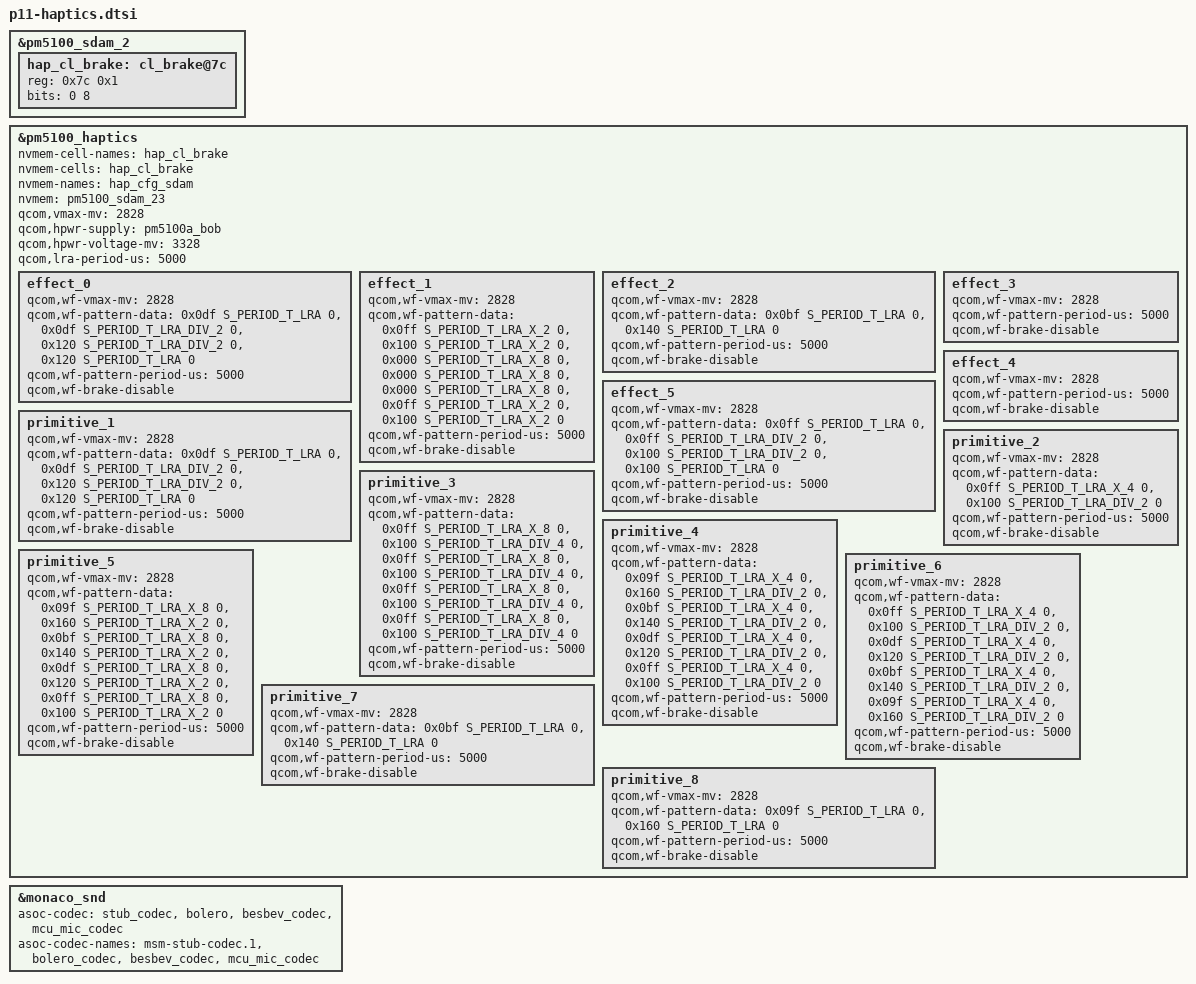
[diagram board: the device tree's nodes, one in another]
// SPDX-License-Identifier: GPL-2.0

&pm5100_sdam_2 {
	#address-cells = <1>;
	#size-cells = <1>;

	hap_cl_brake: cl_brake@7c {
		reg = <0x7c 0x1>;
		bits = <0 8>;
	};
};

&pm5100_haptics {

	nvmem-cell-names = "hap_cl_brake";
	nvmem-cells = <&hap_cl_brake>;
	nvmem-names = "hap_cfg_sdam";
	nvmem = <&pm5100_sdam_23>;
	qcom,vmax-mv = <2828>; // ~Vrms = 2V for LRA
	qcom,hpwr-supply = <&pm5100a_bob>;
	qcom,hpwr-voltage-mv = <3328>; // 3328 - 500mA (Headroom) = 2828 mV = 2Vrms
	qcom,lra-period-us = <5000>;
	status = "okay";

	effect_0 {
		/* CLICK */
		qcom,wf-vmax-mv = <2828>;
		qcom,wf-pattern-data =  <0x0df  S_PERIOD_T_LRA  0>,
					<0x0df  S_PERIOD_T_LRA_DIV_2  0>,
					<0x120  S_PERIOD_T_LRA_DIV_2  0>,
					<0x120  S_PERIOD_T_LRA  0>;
		qcom,wf-pattern-period-us = <5000>;
		qcom,wf-brake-disable;
	};

	effect_1 {
		/* DOUBLE_CLICK */
		qcom,wf-vmax-mv = <2828>;
		qcom,wf-pattern-data =  <0x0ff  S_PERIOD_T_LRA_X_2  0>,
					<0x100  S_PERIOD_T_LRA_X_2  0>,
					<0x000  S_PERIOD_T_LRA_X_8  0>,
					<0x000  S_PERIOD_T_LRA_X_8  0>,
					<0x000  S_PERIOD_T_LRA_X_8  0>,
					<0x0ff  S_PERIOD_T_LRA_X_2  0>,
					<0x100  S_PERIOD_T_LRA_X_2  0>;
		qcom,wf-pattern-period-us = <5000>;
		qcom,wf-brake-disable;
	};

	effect_2 {
		/* TICK */
		qcom,wf-vmax-mv = <2828>;
		qcom,wf-pattern-data =  <0x0bf  S_PERIOD_T_LRA  0>,
					<0x140  S_PERIOD_T_LRA  0>;
		qcom,wf-pattern-period-us = <5000>;
		qcom,wf-brake-disable;
	};

	effect_3 {
		qcom,wf-vmax-mv = <2828>;
		qcom,wf-pattern-period-us = <5000>;
		qcom,wf-brake-disable;
	};

	effect_4 {
		qcom,wf-vmax-mv = <2828>;
		qcom,wf-pattern-period-us = <5000>;
		qcom,wf-brake-disable;
	};

	effect_5 {
		/* HEAVY CLICK */
		qcom,wf-vmax-mv = <2828>;
		qcom,wf-pattern-data =  <0x0ff  S_PERIOD_T_LRA  0>,
					<0x0ff  S_PERIOD_T_LRA_DIV_2  0>,
					<0x100  S_PERIOD_T_LRA_DIV_2  0>,
					<0x100  S_PERIOD_T_LRA  0>;
		qcom,wf-pattern-period-us = <5000>;
		qcom,wf-brake-disable;
	};

	primitive_1 {
		/* CLICK */
		qcom,wf-vmax-mv = <2828>;
		qcom,wf-pattern-data =  <0x0df  S_PERIOD_T_LRA  0>,
					<0x0df  S_PERIOD_T_LRA_DIV_2  0>,
					<0x120  S_PERIOD_T_LRA_DIV_2  0>,
					<0x120  S_PERIOD_T_LRA  0>;
		qcom,wf-pattern-period-us = <5000>;
		qcom,wf-brake-disable;
	};

	primitive_2 {
		/* THUD */
		qcom,wf-vmax-mv = <2828>;
		qcom,wf-pattern-data =  <0x0ff  S_PERIOD_T_LRA_X_4  0>,
					<0x100  S_PERIOD_T_LRA_DIV_2  0>;
		qcom,wf-pattern-period-us = <5000>;
		qcom,wf-brake-disable;
	};

	primitive_3 {
		/* SPIN */
		qcom,wf-vmax-mv = <2828>;
		qcom,wf-pattern-data =  <0x0ff  S_PERIOD_T_LRA_X_8  0>,
					<0x100  S_PERIOD_T_LRA_DIV_4  0>,
					<0x0ff  S_PERIOD_T_LRA_X_8  0>,
					<0x100  S_PERIOD_T_LRA_DIV_4  0>,
					<0x0ff  S_PERIOD_T_LRA_X_8  0>,
					<0x100  S_PERIOD_T_LRA_DIV_4  0>,
					<0x0ff  S_PERIOD_T_LRA_X_8  0>,
					<0x100  S_PERIOD_T_LRA_DIV_4  0>;
		qcom,wf-pattern-period-us = <5000>;
		qcom,wf-brake-disable;
	};

	primitive_4 {
		/* QUICK_RISE */
		qcom,wf-vmax-mv = <2828>;
		qcom,wf-pattern-data =  <0x09f  S_PERIOD_T_LRA_X_4  0>,
					<0x160  S_PERIOD_T_LRA_DIV_2  0>,
					<0x0bf  S_PERIOD_T_LRA_X_4  0>,
					<0x140  S_PERIOD_T_LRA_DIV_2  0>,
					<0x0df  S_PERIOD_T_LRA_X_4  0>,
					<0x120  S_PERIOD_T_LRA_DIV_2  0>,
					<0x0ff  S_PERIOD_T_LRA_X_4  0>,
					<0x100  S_PERIOD_T_LRA_DIV_2  0>;
		qcom,wf-pattern-period-us = <5000>;
		qcom,wf-brake-disable;
	};

	primitive_5 {
		/* SLOW_RISE */
		qcom,wf-vmax-mv = <2828>;
		qcom,wf-pattern-data =  <0x09f  S_PERIOD_T_LRA_X_8  0>,
					<0x160  S_PERIOD_T_LRA_X_2  0>,
					<0x0bf  S_PERIOD_T_LRA_X_8  0>,
					<0x140  S_PERIOD_T_LRA_X_2  0>,
					<0x0df  S_PERIOD_T_LRA_X_8  0>,
					<0x120  S_PERIOD_T_LRA_X_2  0>,
					<0x0ff  S_PERIOD_T_LRA_X_8  0>,
					<0x100  S_PERIOD_T_LRA_X_2  0>;
		qcom,wf-pattern-period-us = <5000>;
		qcom,wf-brake-disable;
	};

	primitive_6 {
		/* QUICK_FALL */
		qcom,wf-vmax-mv = <2828>;
		qcom,wf-pattern-data =  <0x0ff  S_PERIOD_T_LRA_X_4  0>,
					<0x100  S_PERIOD_T_LRA_DIV_2  0>,
					<0x0df  S_PERIOD_T_LRA_X_4  0>,
					<0x120  S_PERIOD_T_LRA_DIV_2  0>,
					<0x0bf  S_PERIOD_T_LRA_X_4  0>,
					<0x140  S_PERIOD_T_LRA_DIV_2  0>,
					<0x09f  S_PERIOD_T_LRA_X_4  0>,
					<0x160  S_PERIOD_T_LRA_DIV_2  0>;
		qcom,wf-pattern-period-us = <5000>;
		qcom,wf-brake-disable;
	};

	primitive_7 {
		/* Light TICK */
		qcom,wf-vmax-mv = <2828>;
		qcom,wf-pattern-data =  <0x0bf  S_PERIOD_T_LRA  0>,
					<0x140  S_PERIOD_T_LRA  0>;
		qcom,wf-pattern-period-us = <5000>;
		qcom,wf-brake-disable;
	};

	primitive_8 {
		/* LOW_TICK */
		qcom,wf-vmax-mv = <2828>;
		qcom,wf-pattern-data =  <0x09f  S_PERIOD_T_LRA  0>,
					<0x160  S_PERIOD_T_LRA  0>;
		qcom,wf-pattern-period-us = <5000>;
		qcom,wf-brake-disable;
	};
};

&monaco_snd {
	asoc-codec  = <&stub_codec>, <&bolero>,
			<&besbev_codec>, <&mcu_mic_codec>;
	asoc-codec-names = "msm-stub-codec.1", "bolero_codec",
				"besbev_codec", "mcu_mic_codec";
};
